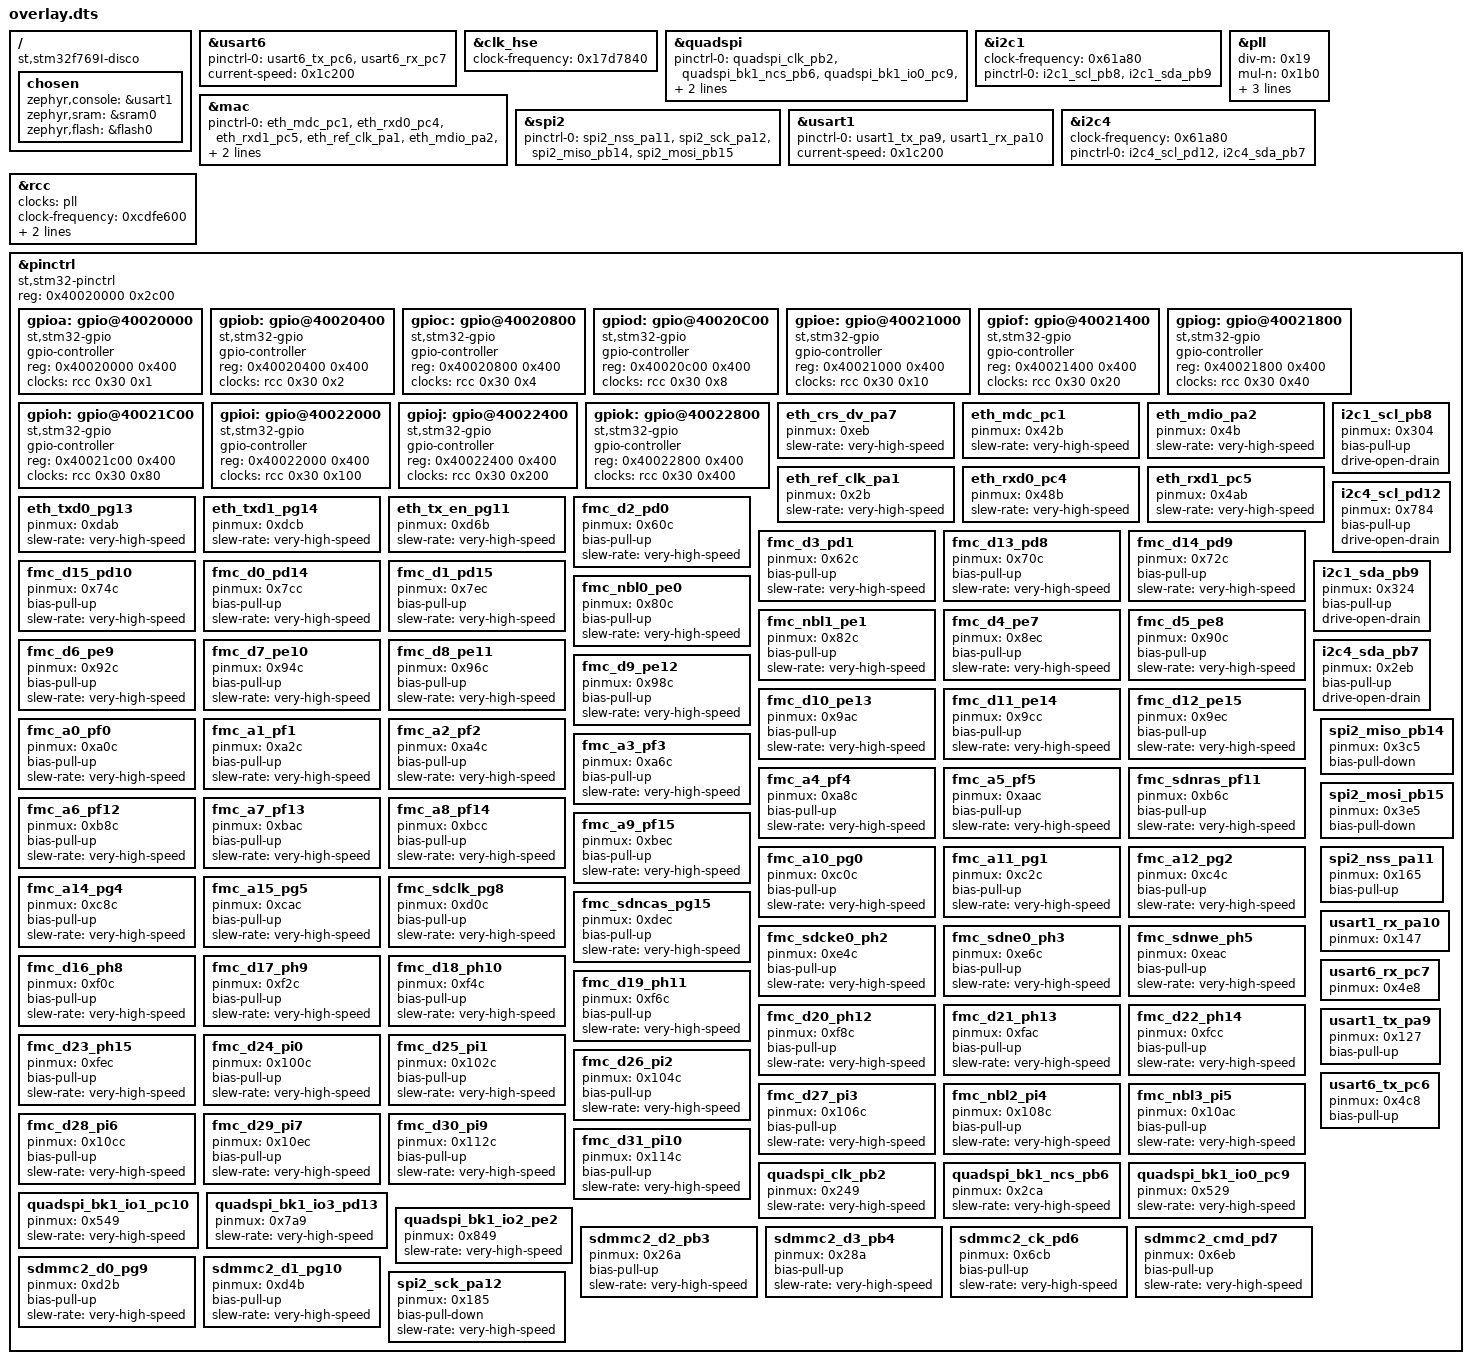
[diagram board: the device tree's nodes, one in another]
/ {
	compatible = "st,stm32f769I-disco";
	chosen {
		zephyr,console = &usart1;
		zephyr,sram = &sram0;
		zephyr,flash = &flash0;
	};
};
&usart6{
	status = "okay";
	pinctrl-0 = < &usart6_tx_pc6 &usart6_rx_pc7 >;
	pinctrl-names = "default";
	current-speed = < 0x1c200 >;
};
&clk_hse{
	status = "okay";
	clock-frequency = < 0x17d7840 >;
};
&quadspi{
	status = "okay";
	pinctrl-0 = < &quadspi_clk_pb2 &quadspi_bk1_ncs_pb6 &quadspi_bk1_io0_pc9 &quadspi_bk1_io1_pc10 &quadspi_bk1_io2_pe2 &quadspi_bk1_io3_pd13 >;
	pinctrl-names = "default";
};
&i2c1{
	clock-frequency = < 0x61a80 >;
	status = "okay";
	pinctrl-0 = < &i2c1_scl_pb8 &i2c1_sda_pb9 >;
	pinctrl-names = "default";
};
&mac{
	status = "okay";
	pinctrl-0 = < &eth_mdc_pc1 &eth_rxd0_pc4 &eth_rxd1_pc5 &eth_ref_clk_pa1 &eth_mdio_pa2 &eth_crs_dv_pa7 &eth_tx_en_pg11 &eth_txd0_pg13 &eth_txd1_pg14 >;
	pinctrl-names = "default";
};
&pll{
	status = "okay";
	div-m = < 0x19 >;
	mul-n = < 0x1b0 >;
	div-p = < 0x2 >;
	div-q = < 0x9 >;
	clocks = < &clk_hse >;
};
&spi2{
	status = "okay";
	pinctrl-0 = < &spi2_nss_pa11 &spi2_sck_pa12 &spi2_miso_pb14 &spi2_mosi_pb15 >;
	pinctrl-names = "default";
};
&usart1{
	status = "okay";
	pinctrl-0 = < &usart1_tx_pa9 &usart1_rx_pa10 >;
	pinctrl-names = "default";
	current-speed = < 0x1c200 >;
};
&i2c4{
	clock-frequency = < 0x61a80 >;
	status = "okay";
	pinctrl-0 = < &i2c4_scl_pd12 &i2c4_sda_pb7 >;
	pinctrl-names = "default";
};
&rcc{
	clocks = < &pll >;
	clock-frequency = < 0xcdfe600 >;
	apb1-prescaler = < 0x4 >;
	apb2-prescaler = < 0x2 >;
};
&pinctrl{
	compatible = "st,stm32-pinctrl";
	#address-cells = < 0x1 >;
	#size-cells = < 0x1 >;
	reg = < 0x40020000 0x2c00 >;
	gpioa: gpio@40020000 {
		compatible = "st,stm32-gpio";
		gpio-controller;
		#gpio-cells = < 0x2 >;
		reg = < 0x40020000 0x400 >;
		clocks = < &rcc 0x30 0x1 >;
	};
	gpiob: gpio@40020400 {
		compatible = "st,stm32-gpio";
		gpio-controller;
		#gpio-cells = < 0x2 >;
		reg = < 0x40020400 0x400 >;
		clocks = < &rcc 0x30 0x2 >;
	};
	gpioc: gpio@40020800 {
		compatible = "st,stm32-gpio";
		gpio-controller;
		#gpio-cells = < 0x2 >;
		reg = < 0x40020800 0x400 >;
		clocks = < &rcc 0x30 0x4 >;
	};
	gpiod: gpio@40020C00 {
		compatible = "st,stm32-gpio";
		gpio-controller;
		#gpio-cells = < 0x2 >;
		reg = < 0x40020c00 0x400 >;
		clocks = < &rcc 0x30 0x8 >;
	};
	gpioe: gpio@40021000 {
		compatible = "st,stm32-gpio";
		gpio-controller;
		#gpio-cells = < 0x2 >;
		reg = < 0x40021000 0x400 >;
		clocks = < &rcc 0x30 0x10 >;
	};
	gpiof: gpio@40021400 {
		compatible = "st,stm32-gpio";
		gpio-controller;
		#gpio-cells = < 0x2 >;
		reg = < 0x40021400 0x400 >;
		clocks = < &rcc 0x30 0x20 >;
	};
	gpiog: gpio@40021800 {
		compatible = "st,stm32-gpio";
		gpio-controller;
		#gpio-cells = < 0x2 >;
		reg = < 0x40021800 0x400 >;
		clocks = < &rcc 0x30 0x40 >;
	};
	gpioh: gpio@40021C00 {
		compatible = "st,stm32-gpio";
		gpio-controller;
		#gpio-cells = < 0x2 >;
		reg = < 0x40021c00 0x400 >;
		clocks = < &rcc 0x30 0x80 >;
	};
	gpioi: gpio@40022000 {
		compatible = "st,stm32-gpio";
		gpio-controller;
		#gpio-cells = < 0x2 >;
		reg = < 0x40022000 0x400 >;
		clocks = < &rcc 0x30 0x100 >;
	};
	gpioj: gpio@40022400 {
		compatible = "st,stm32-gpio";
		gpio-controller;
		#gpio-cells = < 0x2 >;
		reg = < 0x40022400 0x400 >;
		clocks = < &rcc 0x30 0x200 >;
	};
	gpiok: gpio@40022800 {
		compatible = "st,stm32-gpio";
		gpio-controller;
		#gpio-cells = < 0x2 >;
		reg = < 0x40022800 0x400 >;
		clocks = < &rcc 0x30 0x400 >;
	};
	eth_crs_dv_pa7: eth_crs_dv_pa7 {
		pinmux = < 0xeb >;
		slew-rate = "very-high-speed";
	};
	eth_mdc_pc1: eth_mdc_pc1 {
		pinmux = < 0x42b >;
		slew-rate = "very-high-speed";
	};
	eth_mdio_pa2: eth_mdio_pa2 {
		pinmux = < 0x4b >;
		slew-rate = "very-high-speed";
	};
	eth_ref_clk_pa1: eth_ref_clk_pa1 {
		pinmux = < 0x2b >;
		slew-rate = "very-high-speed";
	};
	eth_rxd0_pc4: eth_rxd0_pc4 {
		pinmux = < 0x48b >;
		slew-rate = "very-high-speed";
	};
	eth_rxd1_pc5: eth_rxd1_pc5 {
		pinmux = < 0x4ab >;
		slew-rate = "very-high-speed";
	};
	eth_txd0_pg13: eth_txd0_pg13 {
		pinmux = < 0xdab >;
		slew-rate = "very-high-speed";
	};
	eth_txd1_pg14: eth_txd1_pg14 {
		pinmux = < 0xdcb >;
		slew-rate = "very-high-speed";
	};
	eth_tx_en_pg11: eth_tx_en_pg11 {
		pinmux = < 0xd6b >;
		slew-rate = "very-high-speed";
	};
	fmc_d2_pd0: fmc_d2_pd0 {
		pinmux = < 0x60c >;
		bias-pull-up;
		slew-rate = "very-high-speed";
	};
	fmc_d3_pd1: fmc_d3_pd1 {
		pinmux = < 0x62c >;
		bias-pull-up;
		slew-rate = "very-high-speed";
	};
	fmc_d13_pd8: fmc_d13_pd8 {
		pinmux = < 0x70c >;
		bias-pull-up;
		slew-rate = "very-high-speed";
	};
	fmc_d14_pd9: fmc_d14_pd9 {
		pinmux = < 0x72c >;
		bias-pull-up;
		slew-rate = "very-high-speed";
	};
	fmc_d15_pd10: fmc_d15_pd10 {
		pinmux = < 0x74c >;
		bias-pull-up;
		slew-rate = "very-high-speed";
	};
	fmc_d0_pd14: fmc_d0_pd14 {
		pinmux = < 0x7cc >;
		bias-pull-up;
		slew-rate = "very-high-speed";
	};
	fmc_d1_pd15: fmc_d1_pd15 {
		pinmux = < 0x7ec >;
		bias-pull-up;
		slew-rate = "very-high-speed";
	};
	fmc_nbl0_pe0: fmc_nbl0_pe0 {
		pinmux = < 0x80c >;
		bias-pull-up;
		slew-rate = "very-high-speed";
	};
	fmc_nbl1_pe1: fmc_nbl1_pe1 {
		pinmux = < 0x82c >;
		bias-pull-up;
		slew-rate = "very-high-speed";
	};
	fmc_d4_pe7: fmc_d4_pe7 {
		pinmux = < 0x8ec >;
		bias-pull-up;
		slew-rate = "very-high-speed";
	};
	fmc_d5_pe8: fmc_d5_pe8 {
		pinmux = < 0x90c >;
		bias-pull-up;
		slew-rate = "very-high-speed";
	};
	fmc_d6_pe9: fmc_d6_pe9 {
		pinmux = < 0x92c >;
		bias-pull-up;
		slew-rate = "very-high-speed";
	};
	fmc_d7_pe10: fmc_d7_pe10 {
		pinmux = < 0x94c >;
		bias-pull-up;
		slew-rate = "very-high-speed";
	};
	fmc_d8_pe11: fmc_d8_pe11 {
		pinmux = < 0x96c >;
		bias-pull-up;
		slew-rate = "very-high-speed";
	};
	fmc_d9_pe12: fmc_d9_pe12 {
		pinmux = < 0x98c >;
		bias-pull-up;
		slew-rate = "very-high-speed";
	};
	fmc_d10_pe13: fmc_d10_pe13 {
		pinmux = < 0x9ac >;
		bias-pull-up;
		slew-rate = "very-high-speed";
	};
	fmc_d11_pe14: fmc_d11_pe14 {
		pinmux = < 0x9cc >;
		bias-pull-up;
		slew-rate = "very-high-speed";
	};
	fmc_d12_pe15: fmc_d12_pe15 {
		pinmux = < 0x9ec >;
		bias-pull-up;
		slew-rate = "very-high-speed";
	};
	fmc_a0_pf0: fmc_a0_pf0 {
		pinmux = < 0xa0c >;
		bias-pull-up;
		slew-rate = "very-high-speed";
	};
	fmc_a1_pf1: fmc_a1_pf1 {
		pinmux = < 0xa2c >;
		bias-pull-up;
		slew-rate = "very-high-speed";
	};
	fmc_a2_pf2: fmc_a2_pf2 {
		pinmux = < 0xa4c >;
		bias-pull-up;
		slew-rate = "very-high-speed";
	};
	fmc_a3_pf3: fmc_a3_pf3 {
		pinmux = < 0xa6c >;
		bias-pull-up;
		slew-rate = "very-high-speed";
	};
	fmc_a4_pf4: fmc_a4_pf4 {
		pinmux = < 0xa8c >;
		bias-pull-up;
		slew-rate = "very-high-speed";
	};
	fmc_a5_pf5: fmc_a5_pf5 {
		pinmux = < 0xaac >;
		bias-pull-up;
		slew-rate = "very-high-speed";
	};
	fmc_sdnras_pf11: fmc_sdnras_pf11 {
		pinmux = < 0xb6c >;
		bias-pull-up;
		slew-rate = "very-high-speed";
	};
	fmc_a6_pf12: fmc_a6_pf12 {
		pinmux = < 0xb8c >;
		bias-pull-up;
		slew-rate = "very-high-speed";
	};
	fmc_a7_pf13: fmc_a7_pf13 {
		pinmux = < 0xbac >;
		bias-pull-up;
		slew-rate = "very-high-speed";
	};
	fmc_a8_pf14: fmc_a8_pf14 {
		pinmux = < 0xbcc >;
		bias-pull-up;
		slew-rate = "very-high-speed";
	};
	fmc_a9_pf15: fmc_a9_pf15 {
		pinmux = < 0xbec >;
		bias-pull-up;
		slew-rate = "very-high-speed";
	};
	fmc_a10_pg0: fmc_a10_pg0 {
		pinmux = < 0xc0c >;
		bias-pull-up;
		slew-rate = "very-high-speed";
	};
	fmc_a11_pg1: fmc_a11_pg1 {
		pinmux = < 0xc2c >;
		bias-pull-up;
		slew-rate = "very-high-speed";
	};
	fmc_a12_pg2: fmc_a12_pg2 {
		pinmux = < 0xc4c >;
		bias-pull-up;
		slew-rate = "very-high-speed";
	};
	fmc_a14_pg4: fmc_a14_pg4 {
		pinmux = < 0xc8c >;
		bias-pull-up;
		slew-rate = "very-high-speed";
	};
	fmc_a15_pg5: fmc_a15_pg5 {
		pinmux = < 0xcac >;
		bias-pull-up;
		slew-rate = "very-high-speed";
	};
	fmc_sdclk_pg8: fmc_sdclk_pg8 {
		pinmux = < 0xd0c >;
		bias-pull-up;
		slew-rate = "very-high-speed";
	};
	fmc_sdncas_pg15: fmc_sdncas_pg15 {
		pinmux = < 0xdec >;
		bias-pull-up;
		slew-rate = "very-high-speed";
	};
	fmc_sdcke0_ph2: fmc_sdcke0_ph2 {
		pinmux = < 0xe4c >;
		bias-pull-up;
		slew-rate = "very-high-speed";
	};
	fmc_sdne0_ph3: fmc_sdne0_ph3 {
		pinmux = < 0xe6c >;
		bias-pull-up;
		slew-rate = "very-high-speed";
	};
	fmc_sdnwe_ph5: fmc_sdnwe_ph5 {
		pinmux = < 0xeac >;
		bias-pull-up;
		slew-rate = "very-high-speed";
	};
	fmc_d16_ph8: fmc_d16_ph8 {
		pinmux = < 0xf0c >;
		bias-pull-up;
		slew-rate = "very-high-speed";
	};
	fmc_d17_ph9: fmc_d17_ph9 {
		pinmux = < 0xf2c >;
		bias-pull-up;
		slew-rate = "very-high-speed";
	};
	fmc_d18_ph10: fmc_d18_ph10 {
		pinmux = < 0xf4c >;
		bias-pull-up;
		slew-rate = "very-high-speed";
	};
	fmc_d19_ph11: fmc_d19_ph11 {
		pinmux = < 0xf6c >;
		bias-pull-up;
		slew-rate = "very-high-speed";
	};
	fmc_d20_ph12: fmc_d20_ph12 {
		pinmux = < 0xf8c >;
		bias-pull-up;
		slew-rate = "very-high-speed";
	};
	fmc_d21_ph13: fmc_d21_ph13 {
		pinmux = < 0xfac >;
		bias-pull-up;
		slew-rate = "very-high-speed";
	};
	fmc_d22_ph14: fmc_d22_ph14 {
		pinmux = < 0xfcc >;
		bias-pull-up;
		slew-rate = "very-high-speed";
	};
	fmc_d23_ph15: fmc_d23_ph15 {
		pinmux = < 0xfec >;
		bias-pull-up;
		slew-rate = "very-high-speed";
	};
	fmc_d24_pi0: fmc_d24_pi0 {
		pinmux = < 0x100c >;
		bias-pull-up;
		slew-rate = "very-high-speed";
	};
	fmc_d25_pi1: fmc_d25_pi1 {
		pinmux = < 0x102c >;
		bias-pull-up;
		slew-rate = "very-high-speed";
	};
	fmc_d26_pi2: fmc_d26_pi2 {
		pinmux = < 0x104c >;
		bias-pull-up;
		slew-rate = "very-high-speed";
	};
	fmc_d27_pi3: fmc_d27_pi3 {
		pinmux = < 0x106c >;
		bias-pull-up;
		slew-rate = "very-high-speed";
	};
	fmc_nbl2_pi4: fmc_nbl2_pi4 {
		pinmux = < 0x108c >;
		bias-pull-up;
		slew-rate = "very-high-speed";
	};
	fmc_nbl3_pi5: fmc_nbl3_pi5 {
		pinmux = < 0x10ac >;
		bias-pull-up;
		slew-rate = "very-high-speed";
	};
	fmc_d28_pi6: fmc_d28_pi6 {
		pinmux = < 0x10cc >;
		bias-pull-up;
		slew-rate = "very-high-speed";
	};
	fmc_d29_pi7: fmc_d29_pi7 {
		pinmux = < 0x10ec >;
		bias-pull-up;
		slew-rate = "very-high-speed";
	};
	fmc_d30_pi9: fmc_d30_pi9 {
		pinmux = < 0x112c >;
		bias-pull-up;
		slew-rate = "very-high-speed";
	};
	fmc_d31_pi10: fmc_d31_pi10 {
		pinmux = < 0x114c >;
		bias-pull-up;
		slew-rate = "very-high-speed";
	};
	i2c1_scl_pb8: i2c1_scl_pb8 {
		pinmux = < 0x304 >;
		bias-pull-up;
		drive-open-drain;
	};
	i2c4_scl_pd12: i2c4_scl_pd12 {
		pinmux = < 0x784 >;
		bias-pull-up;
		drive-open-drain;
	};
	i2c1_sda_pb9: i2c1_sda_pb9 {
		pinmux = < 0x324 >;
		bias-pull-up;
		drive-open-drain;
	};
	i2c4_sda_pb7: i2c4_sda_pb7 {
		pinmux = < 0x2eb >;
		bias-pull-up;
		drive-open-drain;
	};
	quadspi_clk_pb2: quadspi_clk_pb2 {
		pinmux = < 0x249 >;
		slew-rate = "very-high-speed";
	};
	quadspi_bk1_ncs_pb6: quadspi_bk1_ncs_pb6 {
		pinmux = < 0x2ca >;
		slew-rate = "very-high-speed";
	};
	quadspi_bk1_io0_pc9: quadspi_bk1_io0_pc9 {
		pinmux = < 0x529 >;
		slew-rate = "very-high-speed";
	};
	quadspi_bk1_io1_pc10: quadspi_bk1_io1_pc10 {
		pinmux = < 0x549 >;
		slew-rate = "very-high-speed";
	};
	quadspi_bk1_io3_pd13: quadspi_bk1_io3_pd13 {
		pinmux = < 0x7a9 >;
		slew-rate = "very-high-speed";
	};
	quadspi_bk1_io2_pe2: quadspi_bk1_io2_pe2 {
		pinmux = < 0x849 >;
		slew-rate = "very-high-speed";
	};
	sdmmc2_d2_pb3: sdmmc2_d2_pb3 {
		pinmux = < 0x26a >;
		bias-pull-up;
		slew-rate = "very-high-speed";
	};
	sdmmc2_d3_pb4: sdmmc2_d3_pb4 {
		pinmux = < 0x28a >;
		bias-pull-up;
		slew-rate = "very-high-speed";
	};
	sdmmc2_ck_pd6: sdmmc2_ck_pd6 {
		pinmux = < 0x6cb >;
		bias-pull-up;
		slew-rate = "very-high-speed";
	};
	sdmmc2_cmd_pd7: sdmmc2_cmd_pd7 {
		pinmux = < 0x6eb >;
		bias-pull-up;
		slew-rate = "very-high-speed";
	};
	sdmmc2_d0_pg9: sdmmc2_d0_pg9 {
		pinmux = < 0xd2b >;
		bias-pull-up;
		slew-rate = "very-high-speed";
	};
	sdmmc2_d1_pg10: sdmmc2_d1_pg10 {
		pinmux = < 0xd4b >;
		bias-pull-up;
		slew-rate = "very-high-speed";
	};
	spi2_miso_pb14: spi2_miso_pb14 {
		pinmux = < 0x3c5 >;
		bias-pull-down;
	};
	spi2_mosi_pb15: spi2_mosi_pb15 {
		pinmux = < 0x3e5 >;
		bias-pull-down;
	};
	spi2_nss_pa11: spi2_nss_pa11 {
		pinmux = < 0x165 >;
		bias-pull-up;
	};
	spi2_sck_pa12: spi2_sck_pa12 {
		pinmux = < 0x185 >;
		bias-pull-down;
		slew-rate = "very-high-speed";
	};
	usart1_rx_pa10: usart1_rx_pa10 {
		pinmux = < 0x147 >;
	};
	usart6_rx_pc7: usart6_rx_pc7 {
		pinmux = < 0x4e8 >;
	};
	usart1_tx_pa9: usart1_tx_pa9 {
		pinmux = < 0x127 >;
		bias-pull-up;
	};
	usart6_tx_pc6: usart6_tx_pc6 {
		pinmux = < 0x4c8 >;
		bias-pull-up;
	};
};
